# WR register map
Vendor: Texas Instruments
Peripheral module from a debugger description file (folder DRA72x).
Registers are 32-bit, access per field, reset 0x0 unless marked. A register's access mark holds for its fields unless they carry their own. Offsets are as the file gives them; lines under a group give offsets from that group; [hi:lo] are bit positions; {n}, {i} and the like mark numbered series; 'fields as' and 'values as' point back to an identical list; <NAME> marks a mode.

## WR
0x00 WR_IDVER ro reset not defined — Subsystem wrapper revision register
  [31:0] REVISION — Wrapper revision value
0x04 WR_SOFT_RESET — Subsystem soft reset register
  [0] SOFT_RESET rw — Software reset - Writing a one to this bit causes the CPGMACSS_R logic to be reset (INT, REGS, CPPI). Software reset occurs on the clock following the register bit write.
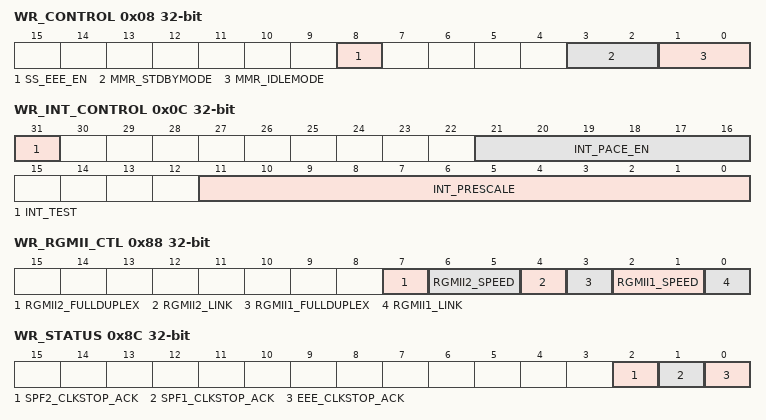
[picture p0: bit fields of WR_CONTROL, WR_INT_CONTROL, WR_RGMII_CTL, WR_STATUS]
0x08 WR_CONTROL — Subsystem control register
  [8] SS_EEE_EN rw — Subsystem Energy Efficient Ethernet enable 0: EEE disabled 1: EEE enabled
  [3:2] MMR_STDBYMODE rw — Configuration of the local initiator state management mode. By definition, initiator may generate read/write transaction as long as it is out of STANDBY state.
    0=EN_0X0 (Force-standby mode : Local initiator is unconditionally placed in standbystate.); 1=EN_0X1 (No-standby mode : Local initiator is unconditionally placed out of standby state.); 3=EN_0X3 (Reserved : Reserved.); 2=EN_0X2 (Reserved : Reserved.)
  [1:0] MMR_IDLEMODE rw — Configuration of the local initiator state management mode. By definition, initiator may generate read/write transaction as long as it is out of IDLE state.
    0=EN_0X0 (Force-idle mode : Local initiator is unconditionally placed in idle state.); 1=EN_0X1 (No-idle mode : Local initiator is unconditionally placed out of idle state.); 3=EN_0X3 (Reserved : Reserved.); 2=EN_0X2 (Reserved : Reserved.)
0x0C WR_INT_CONTROL — Subsystem interrupt control
  [31] INT_TEST rw — Interrupt Test - Test bit to the interrupt pacing blocks
  [21:16] INT_PACE_EN rw — Interrupt Pacing Enable INT_PACE_EN[0] – Enables RX_PULSE Pacing (0 is pacing bypass) INT_PACE_EN[1] – Enables TX_PULSE Pacing (0 is pacing bypass)
  [11:0] INT_PRESCALE ro — Interrupt Counter Prescaler - The number of MAIN_CLK periods in 4us.
0x10 WR_C0_RX_THRESH_EN — Subsystem core 0 receive threshold int enable register
  [7:0] C0_RX_THRESH_EN rw — Core 0 Receive Threshold Enable - Each bit in this register corresponds to the bit in the receive threshold interrupt that is enabled to generate an interrupt on RX_THRESH_PULSE.
0x14 WR_C0_RX_EN — Subsystem core 0 receive interrupt enable register
  [7:0] C0_RX_EN rw — Core 0 Receive Enable - Each bit in this register corresponds to the bit in the rx interrupt that is enabled to generate an interrupt on RX_PULSE.
0x18 WR_C0_TX_EN — Subsystem core 0 transmit interrupt enable register
  [7:0] C0_TX_EN rw — Core 0 Transmit Enable - Each bit in this register corresponds to the bit in the tx interrupt that is enabled to generate an interrupt on TX_PULSE.
0x1C WR_C0_MISC_EN — Subsystem core 0 misc interrupt enable register
  [4:0] C0_MISC_EN rw — Core 0 Misc Enable - Each bit in this register corresponds to the miscellaneous interrupt (SPF2_PEND, SPF1_PEND, EVNT_PEND, STAT_PEND, HOST_PEND, MDIO_LINKINT, MDIO_USERINT) that is enabled to generate an interrupt on MISC_PULSE.
0x40 WR_C0_RX_THRESH_STAT ro — Subsystem core 0 rx threshold masked int status register
  [7:0] C0_RX_THRESH_STAT — Core 0 Receive Threshold Masked Interrupt Status - Each bit in this read only register corresponds to the bit in the receive threshold interrupt that is enabled and generating an interrupt on RX_THRESH_PULSE.
0x44 WR_C0_RX_STAT ro — Subsystem core 0 rx interrupt masked int status register
  [7:0] C0_RX_STAT — Core 0 Receive Masked Interrupt Status - Each bit in this read only register corresponds to the bit in the Rx interrupt that is enabled and generating an interrupt on RX_PULSE.
0x48 WR_C0_TX_STAT ro — Subsystem core 0 tx interrupt masked int status register
  [7:0] C0_TX_STAT — Core 0 Transmit Masked Interrupt Status - Each bit in this read only register corresponds to the bit in the Tx interrupt that is enabled and generating an interrupt on TX_PULSE .
0x4C WR_C0_MISC_STAT ro — Subsystem core 0 misc interrupt masked int status register
  [4:0] C0_MISC_STAT — Core 0 Misc Masked Interrupt Status - Each bit in this register corresponds to the miscellaneous interrupt (SPF2_PEND, SPF1_PEND, EVNT_PEND, STAT_PEND, HOST_PEND, MDIO_LINKINT, MDIO_USERINT) that is enabled and generating an interrupt on MISC_PULSE .
0x70 WR_C0_RX_IMAX — Subsystem core 0 receive interrupts per millisecond
  [5:0] C0_RX_IMAX rw — Core 0 Receive Interrupts per Millisecond - The maximum number of interrupts per millisecond generated on RX_PULSE if pacing is enabled for this interrupt.
0x74 WR_C0_TX_IMAX — Subsystem core 0 transmit interrupts per millisecond
  [5:0] C0_TX_IMAX rw — Core 0 Transmit Interrupts per Millisecond - The maximum number of interrupts per millisecond generated on TX_PULSE if pacing is enabled for this interrupt.
0x88 WR_RGMII_CTL ro — RGMII control signal register
  [7] RGMII2_FULLDUPLEX — RGMII 2 Fullduplex - This is the CPRGMII fullduplex output signal. 0 - Half-duplex mode 1 - Full-duplex mode
  [6:5] RGMII2_SPEED — RGMII2 Speed - This is the CPRGMII speed output signal 0x0 - 10Mbps mode 0x1 - 100Mbps mode 0x2 - 1000Mbps (gig) mode 0x3 - reserved
  [4] RGMII2_LINK — RGMII2 Link Indicator - This is the CPRGMII link output signal 0 - RGMII2 link is down 1 - RGMII2 link is up
  [3] RGMII1_FULLDUPLEX — RGMII1 Fullduplex - This is the CPRGMII fullduplex output signal. 0 - Half-duplex mode 1 - Full-duplex mode
  [2:1] RGMII1_SPEED — RGMII1 Speed - This is the CPRGMII speed output signal 0x0 - 10Mbps mode 0x1 - 100Mbps mode 0x2 - 1000Mbps (gig) mode 0x3 - reserved
  [0] RGMII1_LINK — RGMII1 Link Indicator - This is the CPRGMII link output signal 0 - RGMII1 link is down 1 - RGMII1 link is up
0x8C WR_STATUS ro — Subsystem Status register
  [2] SPF2_CLKSTOP_ACK — SPF2 Clockstop Acknowledge – When asserted the subsystem gated clock is not turned on due to SPF2.
  [1] SPF1_CLKSTOP_ACK — SPF1 Clockstop Acknowledge – When asserted the subsystem gated clock is not turned on due to SPF1.
  [0] EEE_CLKSTOP_ACK — CPSW_3G Clockstop Acknowledge – When asserted the subsystem gated clock is not turned on due to the CPSW_3G.
